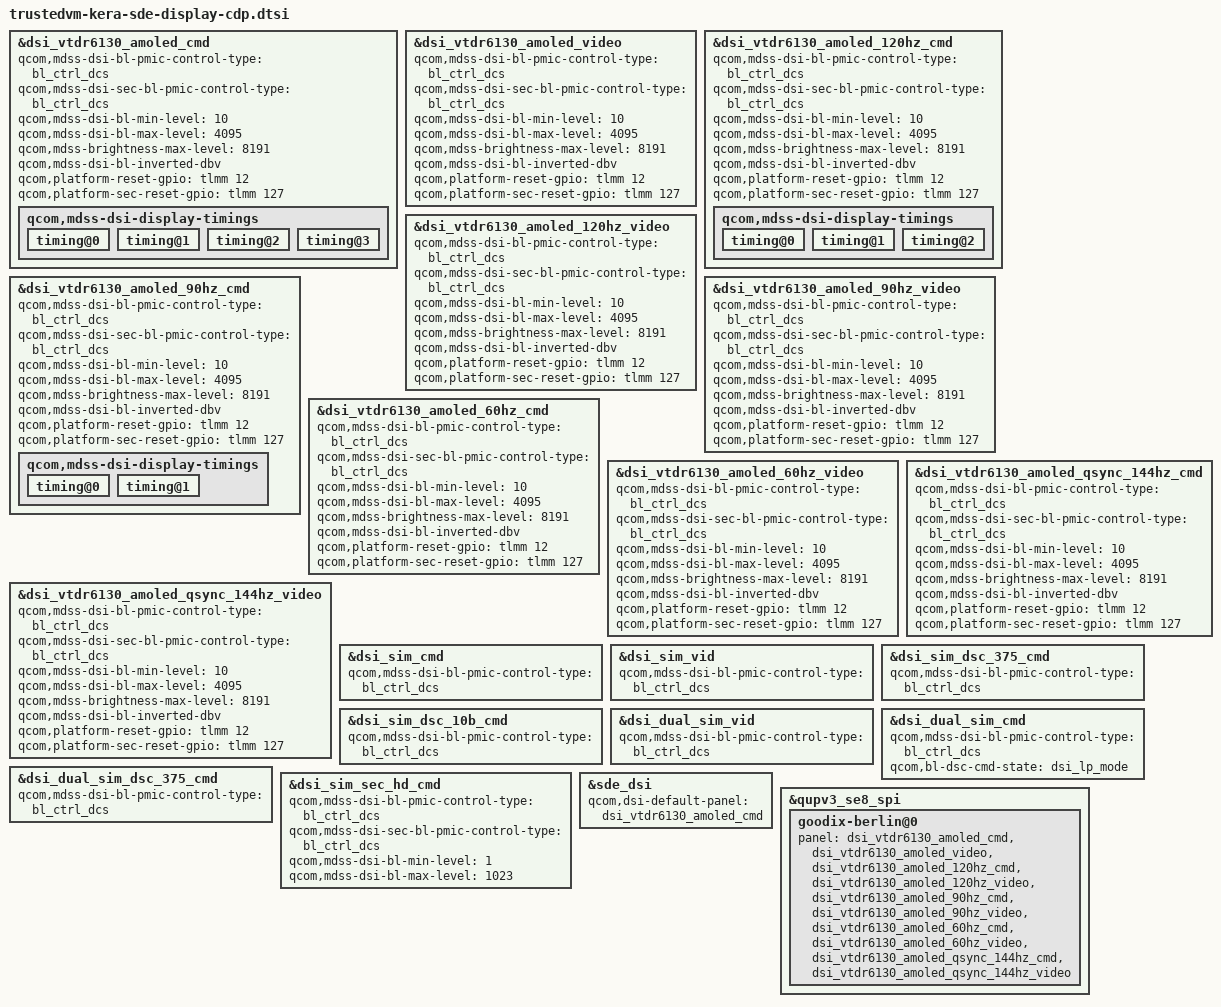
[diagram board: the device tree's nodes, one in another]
// SPDX-License-Identifier: BSD-3-Clause
/*
 * Copyright (c) Qualcomm Technologies, Inc. and/or its subsidiaries.
 */

#include "trustedvm-kera-sde-display.dtsi"

&dsi_vtdr6130_amoled_cmd {
	qcom,mdss-dsi-bl-pmic-control-type = "bl_ctrl_dcs";
	qcom,mdss-dsi-sec-bl-pmic-control-type = "bl_ctrl_dcs";
	qcom,mdss-dsi-bl-min-level = <10>;
	qcom,mdss-dsi-bl-max-level = <4095>;
	qcom,mdss-brightness-max-level = <8191>;
	qcom,mdss-dsi-bl-inverted-dbv;
	qcom,platform-reset-gpio = <&tlmm 12 0>;
	qcom,platform-sec-reset-gpio = <&tlmm 127 0>;

	qcom,mdss-dsi-display-timings {
		timing@0 {
			/delete-property/ qcom,mdss-dsi-panel-clockrate;
		};

		timing@1 {
			/delete-property/ qcom,mdss-dsi-panel-clockrate;
		};

		timing@2 {
			/delete-property/ qcom,mdss-dsi-panel-clockrate;
		};

		timing@3 {
			/delete-property/ qcom,mdss-dsi-panel-clockrate;
		};
	};
};

&dsi_vtdr6130_amoled_video {
	qcom,mdss-dsi-bl-pmic-control-type = "bl_ctrl_dcs";
	qcom,mdss-dsi-sec-bl-pmic-control-type = "bl_ctrl_dcs";
	qcom,mdss-dsi-bl-min-level = <10>;
	qcom,mdss-dsi-bl-max-level = <4095>;
	qcom,mdss-brightness-max-level = <8191>;
	qcom,mdss-dsi-bl-inverted-dbv;
	qcom,platform-reset-gpio = <&tlmm 12 0>;
	qcom,platform-sec-reset-gpio = <&tlmm 127 0>;
};

&dsi_vtdr6130_amoled_120hz_cmd {
	qcom,mdss-dsi-bl-pmic-control-type = "bl_ctrl_dcs";
	qcom,mdss-dsi-sec-bl-pmic-control-type = "bl_ctrl_dcs";
	qcom,mdss-dsi-bl-min-level = <10>;
	qcom,mdss-dsi-bl-max-level = <4095>;
	qcom,mdss-brightness-max-level = <8191>;
	qcom,mdss-dsi-bl-inverted-dbv;
	qcom,platform-reset-gpio = <&tlmm 12 0>;
	qcom,platform-sec-reset-gpio = <&tlmm 127 0>;

	qcom,mdss-dsi-display-timings {
		timing@0 {
			/delete-property/ qcom,mdss-dsi-panel-clockrate;
		};

		timing@1 {
			/delete-property/ qcom,mdss-dsi-panel-clockrate;
		};

		timing@2 {
			/delete-property/ qcom,mdss-dsi-panel-clockrate;
		};
	};
};

&dsi_vtdr6130_amoled_120hz_video {
	qcom,mdss-dsi-bl-pmic-control-type = "bl_ctrl_dcs";
	qcom,mdss-dsi-sec-bl-pmic-control-type = "bl_ctrl_dcs";
	qcom,mdss-dsi-bl-min-level = <10>;
	qcom,mdss-dsi-bl-max-level = <4095>;
	qcom,mdss-brightness-max-level = <8191>;
	qcom,mdss-dsi-bl-inverted-dbv;
	qcom,platform-reset-gpio = <&tlmm 12 0>;
	qcom,platform-sec-reset-gpio = <&tlmm 127 0>;
};

&dsi_vtdr6130_amoled_90hz_cmd {
	qcom,mdss-dsi-bl-pmic-control-type = "bl_ctrl_dcs";
	qcom,mdss-dsi-sec-bl-pmic-control-type = "bl_ctrl_dcs";
	qcom,mdss-dsi-bl-min-level = <10>;
	qcom,mdss-dsi-bl-max-level = <4095>;
	qcom,mdss-brightness-max-level = <8191>;
	qcom,mdss-dsi-bl-inverted-dbv;
	qcom,platform-reset-gpio = <&tlmm 12 0>;
	qcom,platform-sec-reset-gpio = <&tlmm 127 0>;

	qcom,mdss-dsi-display-timings {
		timing@0 {
			/delete-property/ qcom,mdss-dsi-panel-clockrate;
		};

		timing@1 {
			/delete-property/ qcom,mdss-dsi-panel-clockrate;
		};
	};
};

&dsi_vtdr6130_amoled_90hz_video {
	qcom,mdss-dsi-bl-pmic-control-type = "bl_ctrl_dcs";
	qcom,mdss-dsi-sec-bl-pmic-control-type = "bl_ctrl_dcs";
	qcom,mdss-dsi-bl-min-level = <10>;
	qcom,mdss-dsi-bl-max-level = <4095>;
	qcom,mdss-brightness-max-level = <8191>;
	qcom,mdss-dsi-bl-inverted-dbv;
	qcom,platform-reset-gpio = <&tlmm 12 0>;
	qcom,platform-sec-reset-gpio = <&tlmm 127 0>;
};

&dsi_vtdr6130_amoled_60hz_cmd {
	qcom,mdss-dsi-bl-pmic-control-type = "bl_ctrl_dcs";
	qcom,mdss-dsi-sec-bl-pmic-control-type = "bl_ctrl_dcs";
	qcom,mdss-dsi-bl-min-level = <10>;
	qcom,mdss-dsi-bl-max-level = <4095>;
	qcom,mdss-brightness-max-level = <8191>;
	qcom,mdss-dsi-bl-inverted-dbv;
	qcom,platform-reset-gpio = <&tlmm 12 0>;
	qcom,platform-sec-reset-gpio = <&tlmm 127 0>;
};

&dsi_vtdr6130_amoled_60hz_video {
	qcom,mdss-dsi-bl-pmic-control-type = "bl_ctrl_dcs";
	qcom,mdss-dsi-sec-bl-pmic-control-type = "bl_ctrl_dcs";
	qcom,mdss-dsi-bl-min-level = <10>;
	qcom,mdss-dsi-bl-max-level = <4095>;
	qcom,mdss-brightness-max-level = <8191>;
	qcom,mdss-dsi-bl-inverted-dbv;
	qcom,platform-reset-gpio = <&tlmm 12 0>;
	qcom,platform-sec-reset-gpio = <&tlmm 127 0>;
};

&dsi_vtdr6130_amoled_qsync_144hz_cmd {
	qcom,mdss-dsi-bl-pmic-control-type = "bl_ctrl_dcs";
	qcom,mdss-dsi-sec-bl-pmic-control-type = "bl_ctrl_dcs";
	qcom,mdss-dsi-bl-min-level = <10>;
	qcom,mdss-dsi-bl-max-level = <4095>;
	qcom,mdss-brightness-max-level = <8191>;
	qcom,mdss-dsi-bl-inverted-dbv;
	qcom,platform-reset-gpio = <&tlmm 12 0>;
	qcom,platform-sec-reset-gpio = <&tlmm 127 0>;
};

&dsi_vtdr6130_amoled_qsync_144hz_video {
	qcom,mdss-dsi-bl-pmic-control-type = "bl_ctrl_dcs";
	qcom,mdss-dsi-sec-bl-pmic-control-type = "bl_ctrl_dcs";
	qcom,mdss-dsi-bl-min-level = <10>;
	qcom,mdss-dsi-bl-max-level = <4095>;
	qcom,mdss-brightness-max-level = <8191>;
	qcom,mdss-dsi-bl-inverted-dbv;
	qcom,platform-reset-gpio = <&tlmm 12 0>;
	qcom,platform-sec-reset-gpio = <&tlmm 127 0>;
};

&dsi_sim_cmd {
	qcom,mdss-dsi-bl-pmic-control-type = "bl_ctrl_dcs";
};

&dsi_sim_vid {
	qcom,mdss-dsi-bl-pmic-control-type = "bl_ctrl_dcs";
};

&dsi_sim_dsc_375_cmd {
	qcom,mdss-dsi-bl-pmic-control-type = "bl_ctrl_dcs";
};

&dsi_sim_dsc_10b_cmd {
	qcom,mdss-dsi-bl-pmic-control-type = "bl_ctrl_dcs";
};

&dsi_dual_sim_vid {
	qcom,mdss-dsi-bl-pmic-control-type = "bl_ctrl_dcs";
};

&dsi_dual_sim_cmd {
	qcom,mdss-dsi-bl-pmic-control-type = "bl_ctrl_dcs";
	qcom,bl-dsc-cmd-state = "dsi_lp_mode";
};

&dsi_dual_sim_dsc_375_cmd {
	qcom,mdss-dsi-bl-pmic-control-type = "bl_ctrl_dcs";
};

&dsi_sim_sec_hd_cmd {
	qcom,mdss-dsi-bl-pmic-control-type = "bl_ctrl_dcs";
	qcom,mdss-dsi-sec-bl-pmic-control-type = "bl_ctrl_dcs";
	qcom,mdss-dsi-bl-min-level = <1>;
	qcom,mdss-dsi-bl-max-level = <1023>;
};

&sde_dsi {
	qcom,dsi-default-panel = <&dsi_vtdr6130_amoled_cmd>;
};

&qupv3_se8_spi {
	goodix-berlin@0 {
		panel = <&dsi_vtdr6130_amoled_cmd
			&dsi_vtdr6130_amoled_video
			&dsi_vtdr6130_amoled_120hz_cmd
			&dsi_vtdr6130_amoled_120hz_video
			&dsi_vtdr6130_amoled_90hz_cmd
			&dsi_vtdr6130_amoled_90hz_video
			&dsi_vtdr6130_amoled_60hz_cmd
			&dsi_vtdr6130_amoled_60hz_video
			&dsi_vtdr6130_amoled_qsync_144hz_cmd
			&dsi_vtdr6130_amoled_qsync_144hz_video>;
	};
};
